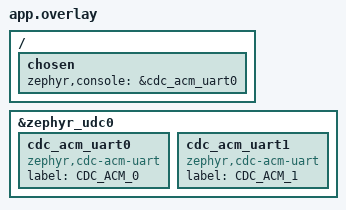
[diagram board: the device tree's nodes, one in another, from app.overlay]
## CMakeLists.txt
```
#
# Copyright (c) 2018 Nordic Semiconductor
#
# SPDX-License-Identifier: LicenseRef-Nordic-5-Clause
#
cmake_minimum_required(VERSION 3.20.0)

find_package(Zephyr REQUIRED HINTS $ENV{ZEPHYR_BASE})
project(traffic_light_ae)

target_sources(app PRIVATE
  src/main.c
  src/onem2m.c

  src/events/ble_event.c
  src/events/ae_event.c
  src/events/led_state_event.c
  src/events/lte_event.c
  src/events/modem_module_event.c
  src/events/peer_conn_event.c
  src/events/uart_data_event.c
  src/events/ut_event.c

  src/modules/ae_module.c
  src/modules/at_handler.c
  src/modules/http_module.c
  src/modules/lte_module.c
  src/modules/led_module.c
  src/modules/modules_common.c
  src/modules/nrf52840_parser.c
  src/modules/uart_handler.c
)

target_include_directories(app PRIVATE
  ${PROJECT_SOURCE_DIR}/include
)

zephyr_library_include_directories(${CMAKE_CURRENT_SOURCE_DIR})
```

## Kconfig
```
menu "Connectivity Bridge"
config BRIDGE_BUF_SIZE
	int "Transport interface buffer size"
	default 4096
	help
	  Size of transmit/receive buffer for transfer between interfaces.

config BRIDGE_UART_BUF_COUNT
	int "UART buffer block count"
	default 3
	range 3 255
	help
	  Number of buffer blocks assigned for UART instances.
	  This value is scaled with the number of interfaces.
	  With the default instance count of 2, and for example 3 buffers,
	  the total will be 6 buffers.
	  Note that all buffers are shared between UART instances.
endmenu

menu "Event Logging"

config LOG_UART_DATA_EVENT
	bool "Enable debug logging of uart data events"
	default false
	help
	  Enables logging of UART data events as they are produced.

config LOG_MODULE_STATE_EVENT
	bool "Enable debug logging of module state events"
	default false
	help
	  Enables logging of module state events as they are produced.

config LOG_PEER_CONN_EVENT
	bool "Enable debug logging of peer connection events"
	default false
	help
	  Enables logging of peer connection events.

endmenu

menu "Zephyr Kernel"
source "Kconfig.zephyr"
endmenu
```

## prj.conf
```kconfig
#
# Copyright (c) 2018 Nordic Semiconductor
#
# SPDX-License-Identifier: LicenseRef-Nordic-5-Clause
#

# Enable App Event Manager
CONFIG_APP_EVENT_MANAGER=y

CONFIG_NEWLIB_LIBC=y
CONFIG_NEWLIB_LIBC_FLOAT_PRINTF=y
CONFIG_FPU=y

# Enable UART logging
CONFIG_CONSOLE_SUBSYS=y
CONFIG_CONSOLE_GETLINE=y
CONFIG_LOG=y
CONFIG_LOG_DEFAULT_LEVEL=4
CONFIG_LOG_MODE_DEFERRED=y
# Network debug config
CONFIG_NET_LOG=y
CONFIG_NET_SOCKETS_LOG_LEVEL_DBG=n
CONFIG_NET_HTTP_LOG_LEVEL_DBG=n
CONFIG_ASSERT=y
CONFIG_PRINTK=y

# UART
CONFIG_UART_CONSOLE=y
CONFIG_UART_INTERRUPT_DRIVEN=y
CONFIG_UART_0_INTERRUPT_DRIVEN=n
CONFIG_UART_1_INTERRUPT_DRIVEN=n
CONFIG_UART_LINE_CTRL=y
CONFIG_UART_ASYNC_API=y
CONFIG_UART_0_ASYNC=y
CONFIG_UART_1_ASYNC=y
CONFIG_UART_0_NRF_HW_ASYNC=y
CONFIG_UART_1_NRF_HW_ASYNC=y
CONFIG_UART_0_NRF_HW_ASYNC_TIMER=1
CONFIG_UART_1_NRF_HW_ASYNC_TIMER=2
CONFIG_NRFX_TIMER1=y
CONFIG_NRFX_TIMER2=y

# LTE
CONFIG_NRF_MODEM_LIB=y
CONFIG_NRF_MODEM_LIB_TRACE=n
CONFIG_LTE_AUTO_INIT_AND_CONNECT=n
CONFIG_LTE_LINK_CONTROL=y
CONFIG_LTE_NETWORK_MODE_LTE_M_GPS=y
CONFIG_AT_MONITOR=y
CONFIG_PDN=y
CONFIG_MODEM_INFO=y
CONFIG_PDN_ESM_STRERROR=y
# The below line prevents TFM from grabbing the UART1 device
CONFIG_TFM_LOG_LEVEL_SILENCE=y

# Networking config
CONFIG_NETWORKING=y
CONFIG_NET_IPV4=y
CONFIG_NET_IPV6=y
CONFIG_NET_SOCKETS=y
CONFIG_NET_SOCKETS_POSIX_NAMES=y
CONFIG_NET_NATIVE=n
CONFIG_NET_SOCKETS_OFFLOAD=y
CONFIG_NET_SOCKETS_POLL_MAX=4
CONFIG_TEST_RANDOM_GENERATOR=n
CONFIG_NET_CONFIG_SETTINGS=y
CONFIG_NET_HOSTNAME_ENABLE=y
CONFIG_NET_HOSTNAME="trafficlightae"
CONFIG_NET_HOSTNAME_UNIQUE=y

# HTTP
CONFIG_HTTP_CLIENT=y
CONFIG_CJSON_LIB=y

# Memory parameters
CONFIG_SYSTEM_WORKQUEUE_STACK_SIZE=4096
CONFIG_SYSTEM_WORKQUEUE_PRIORITY=3
CONFIG_HEAP_MEM_POOL_SIZE=16384
CONFIG_MAIN_STACK_SIZE=4096
CONFIG_RING_BUFFER=y
CONFIG_NRF_MODEM_LIB_HEAP_SIZE=4096
CONFIG_AT_MONITOR_HEAP_SIZE=2048

# Enable bonding
#CONFIG_FLASH=y
#CONFIG_FLASH_PAGE_LAYOUT=y
#CONFIG_FLASH_MAP=y
CONFIG_NVS=y

# CAF - Common Application Framework
CONFIG_CAF=y
CONFIG_LED=y
CONFIG_CAF_LEDS=y
CONFIG_CAF_INIT_LOG_LED_READY_EVENTS=n
CONFIG_CAF_INIT_LOG_LED_EVENTS=n
CONFIG_CAF_INIT_LOG_MODULE_STATE_EVENTS=n
CONFIG_PWM=y
CONFIG_LED_PWM=y
CONFIG_CAF_LEDS_PWM=y

# Enable MCUboot
CONFIG_BOOTLOADER_MCUBOOT=y
CONFIG_SECURE_BOOT=n
CONFIG_BUILD_S1_VARIANT=n
```

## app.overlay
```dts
/*
 * Copyright (c) 2021 Nordic Semiconductor ASA
 *
 * SPDX-License-Identifier: Apache-2.0
 */
 / {
	chosen {
			zephyr,console = &cdc_acm_uart0;
	};
};

 &zephyr_udc0 {
	cdc_acm_uart0: cdc_acm_uart0 {
		compatible = "zephyr,cdc-acm-uart";
		label = "CDC_ACM_0";
	};

	cdc_acm_uart1: cdc_acm_uart1 {
		compatible = "zephyr,cdc-acm-uart";
		label = "CDC_ACM_1";
	};
};
```

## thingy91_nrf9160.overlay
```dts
/*
 * Copyright (c) 2021 Nordic Semiconductor ASA
 *
 * SPDX-License-Identifier: Apache-2.0
 */

 / {
	chosen {
			zephyr,console = &uart0;
	};
};
```

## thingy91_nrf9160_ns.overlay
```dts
/*
 * Copyright (c) 2021 Nordic Semiconductor ASA
 *
 * SPDX-License-Identifier: Apache-2.0
 */

 / {
	chosen {
			zephyr,console = &uart0;
	};
};

// Reenable the UART1 port, it is disabled by the _ns overlay DTS file
&uart1 {
	status = "okay";
};
```

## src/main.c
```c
/*
 * Copyright (c) 2018 Nordic Semiconductor ASA
 *
 * SPDX-License-Identifier: LicenseRef-Nordic-5-Clause
 */

/** @file
 *  @brief Nordic UART Service Client sample
 */

#include <errno.h>
#include <zephyr/kernel.h>
#include <zephyr/sys/printk.h>

#include <zephyr/logging/log.h>

#include <app_event_manager.h>

#define MODULE main
#include <caf/events/module_state_event.h>
#define LOG_MODULE_NAME main
LOG_MODULE_REGISTER(LOG_MODULE_NAME);

void main() {

	if (app_event_manager_init()) {
		LOG_ERR("Application Event Manager not initialized!");
		k_sleep(K_SECONDS(2));
		return;
	} 

	LOG_INF("Application Event Manager initialized.");
	module_set_state(MODULE_STATE_READY);
	LOG_INF("Returned from module_set_state_ready");
	
	while(true) {
		k_sleep(K_SECONDS(10));
		LOG_INF("heartbeat");
	}
}
```

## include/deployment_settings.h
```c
#ifndef TRAFFIC_LIGHT_NRF9160_DEPLOYMENT_SETTINGS_H_
#define TRAFFIC_LIGHT_NRF9160_DEPLOYMENT_SETTINGS_H_
/*
    This file contains constants/settings that may change between each Thingy:91 device.
    These are things such as: ID's, hostnames, serial numbers.
    Do not place any functions in here, only #define statements.
    This file should be changed before programming a new Thingy:91 with the Traffic Light AE so that each AE has a different identifier.
*/
//  http://3.88.130.137/
// Location and port of the oneM2M CSE
#define ENDPOINT_HOSTNAME "34.238.135.110"
#define ENDPOINT_PORT 8080

// Originator name
#define DEVICE_LETTER  "B"
#define M2M_ORIGINATOR "Cthingy91" DEVICE_LETTER
#define BLE_TARGET "Intersection" DEVICE_LETTER

#endif
```

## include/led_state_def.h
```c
/*
 * Copyright (c) 2021 Nordic Semiconductor ASA
 *
 * SPDX-License-Identifier: LicenseRef-Nordic-5-Clause
 */

#include <caf/led_effect.h>
#include "events/led_state_event.h"

/* This configuration file is included only once from led_state module and holds
 * information about LED effects associated with Asset Tracker v2 states.
 */

/* This structure enforces the header file to be included only once in the build.
 * Violating this requirement triggers a multiple definition error at link time.
 */
const struct {} led_state_def_include_once;

enum led_id {
	LED_ID_1,

	LED_ID_COUNT
};

#define LED_PERIOD_NORMAL	350
#define LED_PERIOD_RAPID	100
#define LED_TICKS_DOUBLE	2
#define LED_TICKS_TRIPLE	3

static const struct led_effect traffic_light_led_effect[] = {
	// yellow breath
	[LED_STATE_YELLOW_BREATH]	= LED_EFFECT_LED_BREATH(LED_PERIOD_NORMAL,
								LED_COLOR(120, 80, 0)),
	// green breath
	[LED_STATE_GREEN_BREATH]	= LED_EFFECT_LED_BREATH(LED_PERIOD_NORMAL,
								LED_COLOR(0, 200, 0)),
	// teal breath
	[LED_STATE_TEAL_BREATH]		= LED_EFFECT_LED_BREATH(LED_PERIOD_NORMAL,
								LED_COLOR(0, 150, 150)),
	// blue breath
	[LED_STATE_BLUE_BREATH]	= LED_EFFECT_LED_BREATH(LED_PERIOD_NORMAL,
								LED_COLOR(0, 0, 250)),
	// purple breath
	[LED_STATE_PURPLE_BREATH]	= LED_EFFECT_LED_BREATH(LED_PERIOD_NORMAL,
								LED_COLOR(120, 0, 120)),
	// triple blink green
	[LED_STATE_GREEN_TRIPLE_BLINK]	= LED_EFFECT_LED_CLOCK(LED_TICKS_TRIPLE,
							       LED_COLOR(0, 250, 0)),
	// double blink white
	[LED_STATE_WHITE_DOUBLE_BLINK]	= LED_EFFECT_LED_CLOCK(LED_TICKS_DOUBLE,
							       LED_COLOR(255, 255, 255)),
	// rapid white to off
	[LED_STATE_RAPID_WHITE_OFF]	= LED_EFFECT_LED_ON_GO_OFF(LED_COLOR(255, 255, 255),
								   LED_PERIOD_NORMAL,
								   LED_PERIOD_RAPID),

	// red solid
	[LED_STATE_RED_BREATH]	= LED_EFFECT_LED_BREATH(LED_PERIOD_NORMAL, 
								   LED_COLOR(255, 0, 0)),
	// fast yellow/orange breath
	[LED_STATE_ORANGE_QUICK]	= LED_EFFECT_LED_BREATH(LED_PERIOD_RAPID,
								LED_COLOR(100, 100, 0)),
	// solid yellow/orange
	[LED_STATE_ORANGE_SOLID]	= LED_EFFECT_LED_ON(LED_COLOR(255, 165, 0)),
	[LED_STATE_TURN_OFF]		= LED_EFFECT_LED_OFF(),
};
```

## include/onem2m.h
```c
#ifndef TRAFFIC_LIGHT_NRF9160_ONEM2M_H_
#define TRAFFIC_LIGHT_NRF9160_ONEM2M_H_

void init_oneM2M();

// Access Control Policy (ACP)
void createACP();
bool discoverACP();
bool deleteACP();

// Application Entity (AE)
char* createAE();
bool discoverAE();
bool deleteAE();

// Flex Container
char* createFlexContainer();
bool discoverFlexContainer();
bool deleteFLEX();
void retrieveFlexContainer();
bool updateFlexContainer(const char* l1s, const char* l2s, const char* bts);

// Polling Channel (PCH)
void createPCH();
bool discoverPCH();
bool deletePCH();
void onem2m_performPoll();

// Subscriptions (SUB)
void createSUB();
bool discoverSUB();
bool deleteSUB();

#endif // TRAFFIC_LIGHT_NRF9160_ONEM2M_H_
```

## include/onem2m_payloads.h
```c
#ifndef TRAFFIC_LIGHT_NRF9160_ONEM2M_PAYLOADS_H_
#define TRAFFIC_LIGHT_NRF9160_ONEM2M_PAYLOADS_H_

/*
    This file holds oneM2M request payloads.
    Helps clear up the oneM2M.c file.
*/

#include "deployment_settings.h"

static char* acp_create_payload = "{\
\"m2m:acp\":{\"rn\": \"" M2M_ORIGINATOR "-ACP\",\"pv\": {\"acr\": [{\"acor\":[\"Cdashboard\",\"Cdashboard1\",\"Cdashboard2\",\"Cdashboard3\",\"Cdashboard4\",\"Cdashboard5\",\"Cdashboard6\",\"Cdashboard7\",\"Cdashboard8\",\"Cdashboard9\",\"Cdashboard10\"], \"acop\": 63},\
{\"acor\":[\"" M2M_ORIGINATOR "\"], \"acop\": 63}]},\"pvs\": {\"acr\": [\
{\"acor\":[\"Cdashboard\",\"Cdashboard1\",\"Cdashboard2\",\"Cdashboard3\",\"Cdashboard4\",\"Cdashboard5\",\"Cdashboard6\",\"Cdashboard7\",\"Cdashboard8\",\"Cdashboard9\",\"Cdashboard10\"], \"acop\": 63},\
{\"acor\":[\"" M2M_ORIGINATOR "\"], \"acop\": 63}]}}}";

static char* ae_create_payload = "{\
    \"m2m:ae\": {\
        \"acpi\": [\
            \"%s\"\
        ],\
        \"api\": \"NtrafficAPI\",\
        \"rn\": \"intersection" DEVICE_LETTER "\",\
        \"srv\": [\
            \"3\"\
        ],\
        \"rr\": false\
    }\
}";

static char* flex_container_create_payload = "{\
    \"traffic:trfint\": {\
        \"acpi\": [\
            \"%s\"\
        ],\
        \"cnd\": \"edu.psu.cse.traffic.trafficLightIntersection\",\
        \"rn\": \"intersection\",\
        \"l1s\": \"red\",\
        \"l2s\": \"red\",\
        \"bts\": \"disconnected\"\
    }\
}";

static char* pch_ack_payload = "{\"m2m:rsp\":{\"rqi\": \"%s\", \"pc\": %s, \"rsc\": 2004, \"rvi\": \"3\" }}";

#endif // TRAFFIC_LIGHT_NRF9160_ONEM2M_PAYLOADS_H_
```
